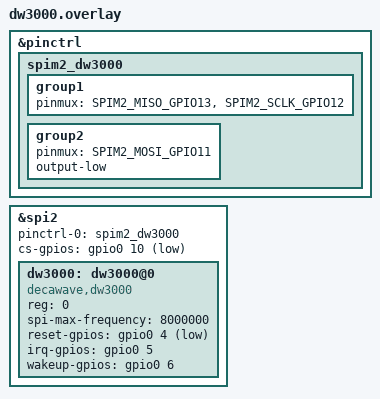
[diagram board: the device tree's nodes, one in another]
/*
 * DW3000 (DWM3000EVB) on ESP32-S3 SPI2 (FSPI) — Woz UWB ranging engine.
 *
 * Reference wiring for esp32s3_devkitc/esp32s3/procpu. The pin numbers below are
 * an EXAMPLE: change them to match how you soldered the DWM3000EVB to your board.
 * The DW3000 driver is the generic Zephyr one (deps/dw3000/platform), so only
 * this devicetree node changes between boards — no C is touched.
 *
 *   SCLK GPIO12   MOSI GPIO11   MISO GPIO13   CS GPIO10
 *   RSTn GPIO4    IRQ  GPIO5    WAKEUP GPIO6
 *
 * See ports/esp32s3/README.md and docs/porting.md.
 */
#include <zephyr/dt-bindings/pinctrl/esp32s3-pinctrl.h>
#include <zephyr/dt-bindings/gpio/gpio.h>

&pinctrl {
	spim2_dw3000: spim2_dw3000 {
		group1 {
			pinmux = <SPIM2_MISO_GPIO13>,
				 <SPIM2_SCLK_GPIO12>;
		};
		group2 {
			pinmux = <SPIM2_MOSI_GPIO11>;
			output-low;
		};
	};
};

&spi2 {
	status = "okay";
	pinctrl-0 = <&spim2_dw3000>;
	pinctrl-names = "default";
	/* CS is a plain GPIO in Zephyr's SPI model (not a SPIM2_CSEL pinmux). */
	cs-gpios = <&gpio0 10 GPIO_ACTIVE_LOW>;

	dw3000: dw3000@0 {
		compatible = "decawave,dw3000";
		reg = <0>;
		/* 8 MHz: proven safe with a seated DWM3000EVB (matches the nRF overlay).
		 * Raise once your wiring is confirmed clean. */
		spi-max-frequency = <8000000>;
		reset-gpios  = <&gpio0 4 GPIO_ACTIVE_LOW>;
		irq-gpios    = <&gpio0 5 GPIO_ACTIVE_HIGH>;
		wakeup-gpios = <&gpio0 6 GPIO_ACTIVE_HIGH>;
	};
};
